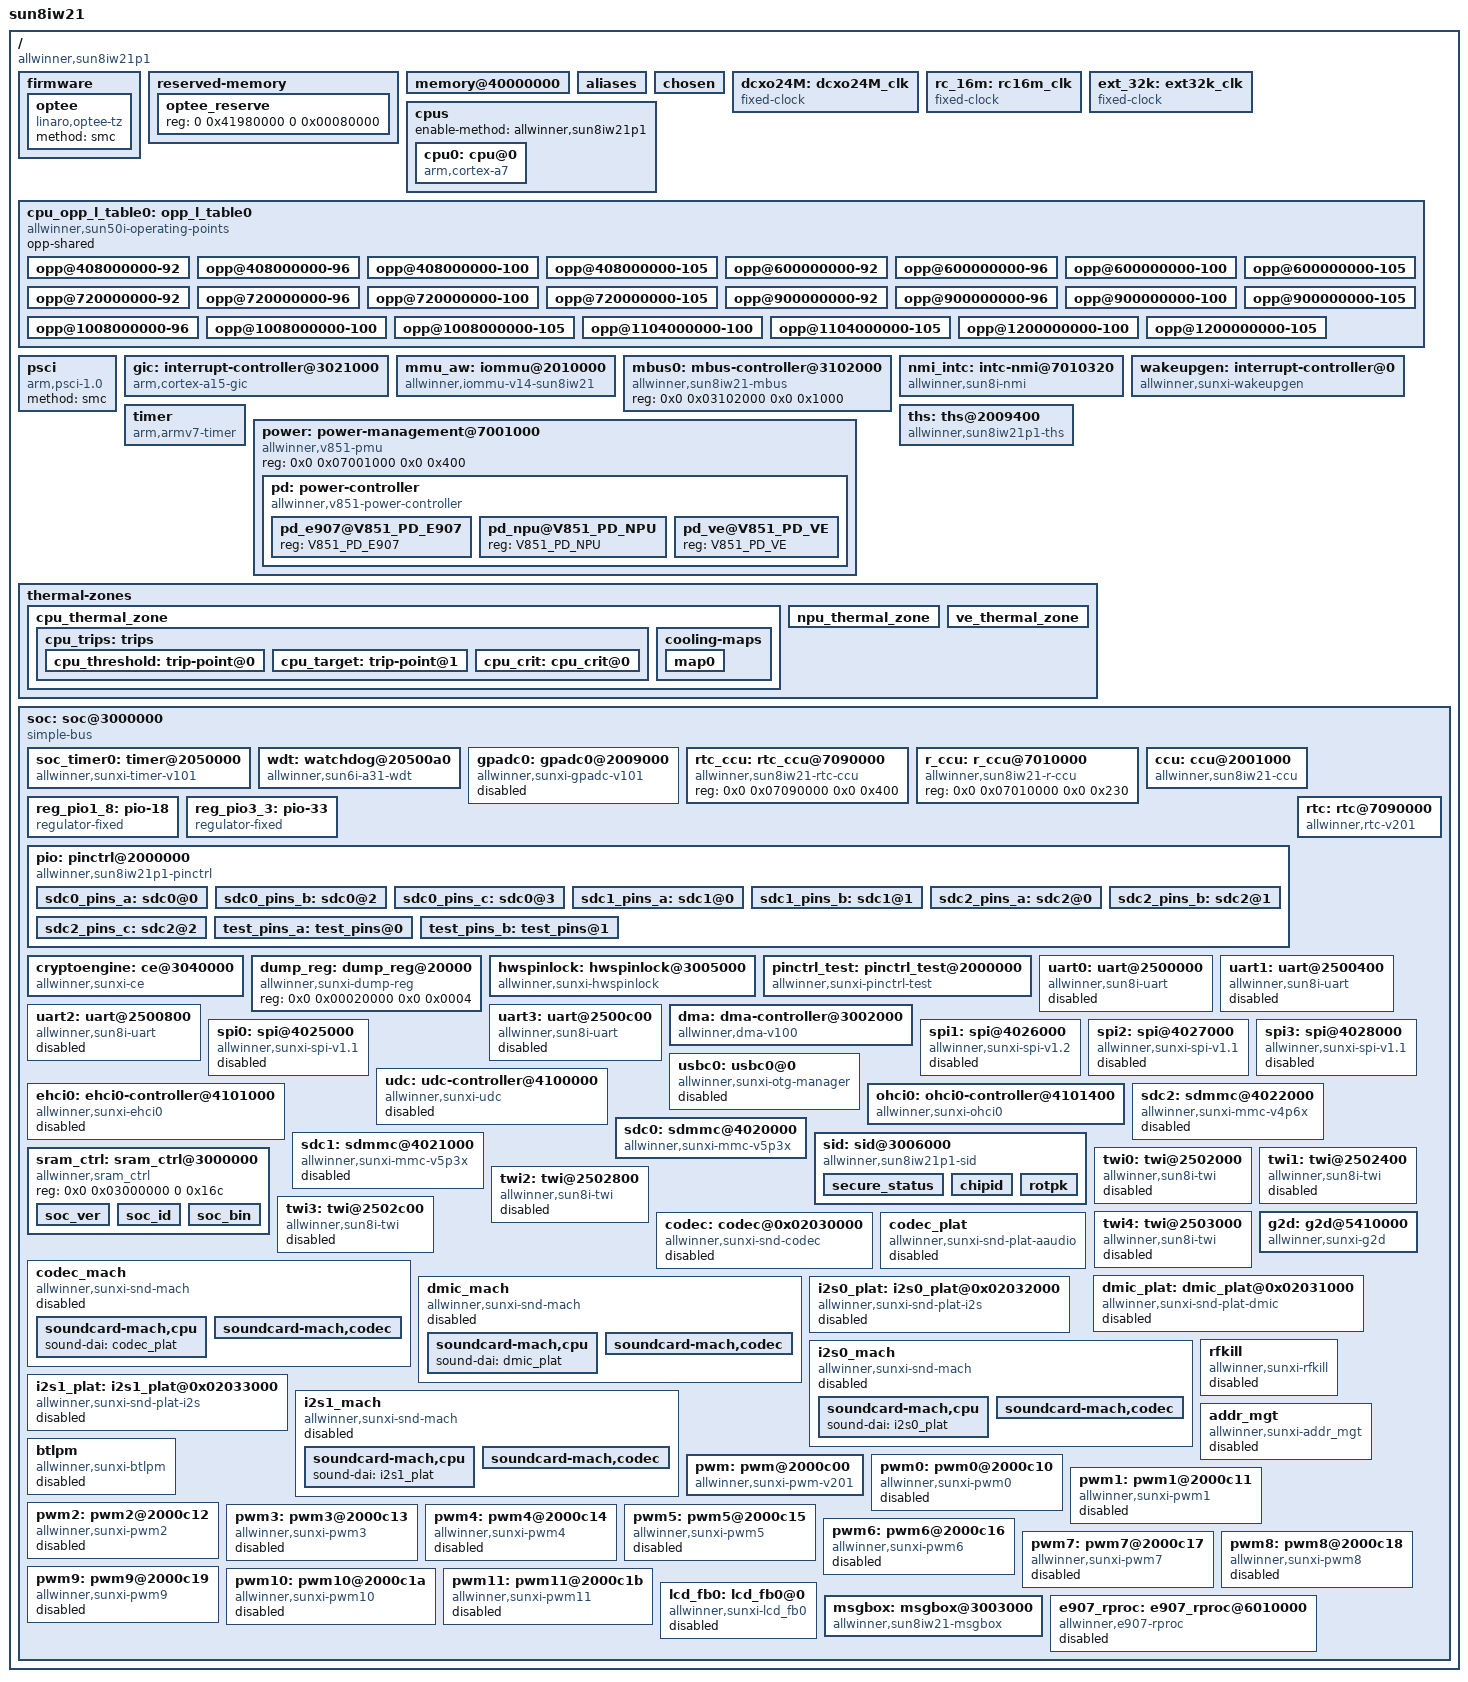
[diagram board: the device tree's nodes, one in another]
/* SPDX-License-Identifier: GPL-2.0-or-later */
/*
 * Allwinner Technology CO., Ltd. sun8iw21p1 platform
 *
 * modify base on juno.dts
 */

/* kernel used */
#include <dt-bindings/interrupt-controller/arm-gic.h>
#include <dt-bindings/gpio/gpio.h>
#include <dt-bindings/thermal/thermal.h>
#include <dt-bindings/power/v851-power.h>
#include <dt-bindings/reset/sun8iw21-ccu.h>
#include <dt-bindings/reset/sun8iw21-r-ccu.h>
#include <dt-bindings/clock/sun8iw21-ccu.h>
#include <dt-bindings/clock/sun8iw21-rtc.h>
#include <dt-bindings/clock/sun8iw21-r-ccu.h>
#include <dt-bindings/gpio/sun4i-gpio.h>
#include <dt-bindings/spi/sunxi-spi.h>

/ {
	model = "sun8iw21";
	compatible = "allwinner,sun8iw21p1";
	interrupt-parent = <&wakeupgen>;
	#address-cells = <2>;
	#size-cells = <2>;

	firmware {
		optee {
			compatible = "linaro,optee-tz";
			method = "smc";
		};
	};

	reserved-memory {
		#address-cells = <2>;
		#size-cells = <2>;
		ranges;

		optee_reserve {
			reg = <0 0x41980000 0 0x00080000>; /* size must be set 0x80000 in secure */
			status = "okay";
		};
	};

	memory@40000000 {
		device_type = "memory";
		reg = <0x00000000 0x40000000 0x00000000 0x20000000>;
	};

	aliases {
		serial0 = &uart0;
		serial1 = &uart1;
		serial2 = &uart2;
		serial3 = &uart3;
		spi0 = &spi0;
		spi1 = &spi1;
		spi2 = &spi2;
		spi3 = &spi3;
		gpadc0 = &gpadc0;
		sunxi-mmc0 = &sdc0;
		sunxi-mmc2 = &sdc2;
		twi0 = &twi0;
		twi1 = &twi1;
		twi2 = &twi2;
		twi3 = &twi3;
		twi4 = &twi4;
	};

	chosen {
		bootargs = "earlyprintk=sunxi-uart,0x02500000 loglevel=8 initcall_debug=0 console=ttyS0 init=/init";
		linux,initrd-start = <0x0 0x0>;
		linux,initrd-end = <0x0 0x0>;
	};

	dcxo24M: dcxo24M_clk {
		#clock-cells = <0>;
		compatible = "fixed-clock";
		clock-frequency = <24000000>;
		clock-output-names = "dcxo24M";
	};

	rc_16m: rc16m_clk {
		#clock-cells = <0>;
		compatible = "fixed-clock";
		clock-frequency = <16000000>;
		clock-accuracy = <300000000>;
		clock-output-names = "rc-16m";
	};

	ext_32k: ext32k_clk {
		#clock-cells = <0>;
		compatible = "fixed-clock";
		clock-frequency = <32768>;
		clock-output-names = "ext-32k";
	};

	cpus {
		enable-method = "allwinner,sun8iw21p1";
		#address-cells = <1>;
		#size-cells = <0>;

		cpu0: cpu@0 {
			device_type = "cpu";
			compatible = "arm,cortex-a7";
			reg = <0x0>;
			enable-method = "psci";
			vf_tbl_sel = <0>;
			clocks = <&ccu CLK_CPU>;
			clock-frequency = <1008000000>;
			clock-latency = <2000000>;
			cooling-min-level = <5>;
			cooling-max-level = <0>;
			#cooling-cells = <2>; /* min followed by max */
			dynamic-power-coefficient = <142>;
			operating-points-v2 = <&cpu_opp_l_table0>;
		};

	};

	cpu_opp_l_table0: opp_l_table0 {
		/* compatible = "operating-points-v2"; */
		compatible = "allwinner,sun50i-operating-points";
		opp-shared;
		/* compatible = "allwinner,opp_l_table0"; */

		opp@408000000-92 {
			opp-hz = /bits/ 64 <408000000>;
			opp-microvolt = <920000>;
			clock-latency-ns = <244144>; /* 8 32k periods */
			opp-supported-hw = <0x42B>;
		};
		opp@408000000-96 {
			opp-hz = /bits/ 64 <408000000>;
			opp-microvolt = <960000>;
			clock-latency-ns = <244144>; /* 8 32k periods */
			opp-supported-hw = <0xA54>;
		};
		opp@408000000-100 {
			opp-hz = /bits/ 64 <408000000>;
			opp-microvolt = <1000000>;
			clock-latency-ns = <244144>; /* 8 32k periods */
			opp-supported-hw = <0x80>;
		};
		opp@408000000-105 {
			opp-hz = /bits/ 64 <408000000>;
			opp-microvolt = <1050000>;
			clock-latency-ns = <244144>; /* 8 32k periods */
			opp-supported-hw = <0x100>;
		};
		opp@600000000-92 {
			opp-hz = /bits/ 64 <600000000>;
			opp-microvolt = <920000>;
			clock-latency-ns = <244144>; /* 8 32k periods */
			opp-supported-hw = <0x42B>;
		};
		opp@600000000-96 {
			opp-hz = /bits/ 64 <600000000>;
			opp-microvolt = <960000>;
			clock-latency-ns = <244144>; /* 8 32k periods */
			opp-supported-hw = <0xA54>;
		};
		opp@600000000-100 {
			opp-hz = /bits/ 64 <600000000>;
			opp-microvolt = <1000000>;
			clock-latency-ns = <244144>; /* 8 32k periods */
			opp-supported-hw = <0x80>;
		};
		opp@600000000-105 {
			opp-hz = /bits/ 64 <600000000>;
			opp-microvolt = <1050000>;
			clock-latency-ns = <244144>; /* 8 32k periods */
			opp-supported-hw = <0x100>;
		};
		opp@720000000-92 {
			opp-hz = /bits/ 64 <720000000>;
			opp-microvolt = <920000>;
			clock-latency-ns = <244144>; /* 8 32k periods */
			opp-supported-hw = <0x42B>;
		};
		opp@720000000-96 {
			opp-hz = /bits/ 64 <720000000>;
			opp-microvolt = <960000>;
			clock-latency-ns = <244144>; /* 8 32k periods */
			opp-supported-hw = <0xA54>;
		};
		opp@720000000-100 {
			opp-hz = /bits/ 64 <720000000>;
			opp-microvolt = <1000000>;
			clock-latency-ns = <244144>; /* 8 32k periods */
			opp-supported-hw = <0x80>;
		};
		opp@720000000-105 {
			opp-hz = /bits/ 64 <720000000>;
			opp-microvolt = <1050000>;
			clock-latency-ns = <244144>; /* 8 32k periods */
			opp-supported-hw = <0x100>;
		};
		opp@900000000-92 {
			opp-hz = /bits/ 64 <900000000>;
			opp-microvolt = <920000>;
			clock-latency-ns = <244144>; /* 8 32k periods */
			opp-supported-hw = <0x42B>;
		};
		opp@900000000-96 {
			opp-hz = /bits/ 64 <900000000>;
			opp-microvolt = <960000>;
			clock-latency-ns = <244144>; /* 8 32k periods */
			opp-supported-hw = <0xA54>;
		};
		opp@900000000-100 {
			opp-hz = /bits/ 64 <900000000>;
			opp-microvolt = <1000000>;
			clock-latency-ns = <244144>; /* 8 32k periods */
			opp-supported-hw = <0x80>;
		};
		opp@900000000-105 {
			opp-hz = /bits/ 64 <900000000>;
			opp-microvolt = <1050000>;
			clock-latency-ns = <244144>; /* 8 32k periods */
			opp-supported-hw = <0x100>;
		};
		opp@1008000000-96 {
			opp-hz = /bits/ 64 <1008000000>;
			opp-microvolt = <960000>;
			clock-latency-ns = <244144>; /* 8 32k periods */
			opp-supported-hw = <0xE54>;
		};
		opp@1008000000-100 {
			opp-hz = /bits/ 64 <1008000000>;
			opp-microvolt = <1000000>;
			clock-latency-ns = <244144>; /* 8 32k periods */
			opp-supported-hw = <0x80>;
		};
		opp@1008000000-105 {
			opp-hz = /bits/ 64 <1008000000>;
			opp-microvolt = <1050000>;
			clock-latency-ns = <244144>; /* 8 32k periods */
			opp-supported-hw = <0x100>;
		};
		opp@1104000000-100 {
			opp-hz = /bits/ 64 <1104000000>;
			opp-microvolt = <1000000>;
			clock-latency-ns = <244144>; /* 8 32k periods */
			opp-supported-hw = <0xC80>;
		};
		opp@1104000000-105 {
			opp-hz = /bits/ 64 <1104000000>;
			opp-microvolt = <1050000>;
			clock-latency-ns = <244144>; /* 8 32k periods */
			opp-supported-hw = <0x100>;
		};
		opp@1200000000-100 {
			opp-hz = /bits/ 64 <1200000000>;
			opp-microvolt = <1000000>;
			clock-latency-ns = <244144>; /* 8 32k periods */
			opp-supported-hw = <0x80>;
		};
		opp@1200000000-105 {
			opp-hz = /bits/ 64 <1200000000>;
			opp-microvolt = <1050000>;
			clock-latency-ns = <244144>; /* 8 32k periods */
			opp-supported-hw = <0x100>;
		};
	};

	psci {
		compatible = "arm,psci-1.0";
		method = "smc";
	};

	gic: interrupt-controller@3021000 {
		compatible = "arm,cortex-a15-gic", "arm,cortex-a9-gic";
		#interrupt-cells = <3>;
		#address-cells = <0>;
		device_type = "gic";
		interrupt-controller;
		reg = <0x0 0x03021000 0 0x1000>, /* GIC Dist */
		      <0x0 0x03022000 0 0x2000>, /* GIC CPU */
		      <0x0 0x03024000 0 0x2000>, /* GIC VCPU Control */
		      <0x0 0x03026000 0 0x2000>; /* GIC VCPU */
		interrupts = <GIC_PPI 9 0xf04>; /* GIC Maintenence IRQ */
		interrupt-parent = <&gic>;
	};

	mmu_aw: iommu@2010000 {
		compatible = "allwinner,iommu-v14-sun8iw21";
		reg = <0x0 0x02010000 0x0 0x400>;
		interrupts = <GIC_SPI 64 IRQ_TYPE_LEVEL_HIGH>;
		interrupt-names = "iommu-irq";
		clocks = <&ccu CLK_IOMMU>;
		clock-names = "iommu";
		/* clock-frequency = <24000000>; */
		#iommu-cells = <2>;
		status = "okay";
	};

	mbus0: mbus-controller@3102000 {
		compatible = "allwinner,sun8iw21-mbus";
		reg = <0x0 0x03102000 0x0 0x1000>;
		#mbus-cells = <1>;
		status = "okay";
	};

	nmi_intc: intc-nmi@7010320 {
		compatible = "allwinner,sun8i-nmi";
		interrupt-parent = <&gic>;
		#interrupt-cells = <2>;
		#address-cells = <0>;
		interrupt-controller;
		reg = <0x0 0x07010320 0 0xc>;
		pad-control-v2 = <0x07090230>;
		pad-control-offset = <30>;
		pad-control-en = <0>;
		interrupts = <GIC_SPI 136 IRQ_TYPE_LEVEL_HIGH>;
	};

	wakeupgen: interrupt-controller@0 {
		compatible = "allwinner,sunxi-wakeupgen";
		interrupt-controller;
		#interrupt-cells = <3>;
		interrupt-parent = <&gic>;
	};

	timer {
		compatible = "arm,armv7-timer";
		interrupts = <GIC_PPI 13 (GIC_CPU_MASK_SIMPLE(2) | IRQ_TYPE_LEVEL_LOW)>, /* Secure Phys IRQ */
			     <GIC_PPI 14 (GIC_CPU_MASK_SIMPLE(2) | IRQ_TYPE_LEVEL_LOW)>, /* Non-secure Phys IRQ */
			     <GIC_PPI 11 (GIC_CPU_MASK_SIMPLE(2) | IRQ_TYPE_LEVEL_LOW)>, /* Virt IRQ */
			     <GIC_PPI 10 (GIC_CPU_MASK_SIMPLE(2) | IRQ_TYPE_LEVEL_LOW)>; /* Hyp IRQ */
		clock-frequency = <24000000>;
		arm,cpu-registers-not-fw-configured;
		interrupt-parent = <&gic>;
		arm,no-tick-in-suspend;
	};

	power: power-management@7001000 {
		compatible = "allwinner,v851-pmu", "syscon", "simple-mfd";
		reg = <0x0 0x07001000 0x0 0x400>;

		pd: power-controller {
			compatible = "allwinner,v851-power-controller";
			clocks = <&r_ccu CLK_R_PPU>;
			clock-names = "ppu";
			resets = <&r_ccu RST_BUS_R_PPU>;
			reset-names = "ppu_rst";
			#power-domain-cells = <1>;
			#address-cells = <1>;
			#size-cells = <0>;

			pd_e907@V851_PD_E907 {
				reg = <V851_PD_E907>;
			};
			pd_npu@V851_PD_NPU {
				reg = <V851_PD_NPU>;
			};
			pd_ve@V851_PD_VE {
				reg = <V851_PD_VE>;
			};
		};
	};

	ths: ths@2009400 {
		compatible = "allwinner,sun8iw21p1-ths";
		reg = <0x0 0x02009400 0x0 0x400>;
		clocks = <&ccu CLK_THS>,<&ccu CLK_GPADC_24M>;
		clock-names = "bus","gpadc";
		resets = <&ccu RST_BUS_TH>;
		#thermal-sensor-cells = <1>;
	};

	thermal-zones {
		cpu_thermal_zone {
			polling-delay-passive = <500>;
			polling-delay = <1000>;
			thermal-sensors = <&ths 2>;
			sustainable-power = <68>;

			cpu_trips: trips {
				cpu_threshold: trip-point@0 {
					temperature = <70000>;
					type = "passive";
					hysteresis = <0>;
				};
				cpu_target: trip-point@1 {
					temperature = <90000>;
					type = "passive";
					hysteresis = <0>;
				};
				cpu_crit: cpu_crit@0 {
					temperature = <110000>;
					type = "critical";
					hysteresis = <0>;
				};
			};

			cooling-maps {
				map0 {
					trip = <&cpu_target>;
					cooling-device = <&cpu0
					THERMAL_NO_LIMIT
					THERMAL_NO_LIMIT>;
					contribution = <1024>;
				};
			};
		};
		npu_thermal_zone {
			polling-delay-passive = <0>;
			polling-delay = <0>;
			thermal-sensors = <&ths 0>;
		};
		ve_thermal_zone {
			polling-delay-passive = <0>;
			polling-delay = <0>;
			thermal-sensors = <&ths 1>;
		};
	};

	soc: soc@3000000 {
		compatible = "simple-bus";
		#address-cells = <2>;
		#size-cells = <2>;
		ranges;
		device_type = "soc";

		soc_timer0: timer@2050000 {
			compatible = "allwinner,sunxi-timer-v101";
			device_type = "soc_timer";
			reg = <0x0 0x02050000 0x0 0x90>;
			interrupts = <GIC_SPI 59 IRQ_TYPE_LEVEL_HIGH>;
			clocks = <&dcxo24M>, <&rtc_ccu CLK_OSC32K>;
		};

		wdt: watchdog@20500a0 {
			compatible = "allwinner,sun6i-a31-wdt";
			reg = <0x0 0x020500a0 0x0 0x20>;
			interrupts = <GIC_SPI 63 IRQ_TYPE_LEVEL_HIGH>;
		};

		gpadc0: gpadc0@2009000 {
			compatible = "allwinner,sunxi-gpadc-v101";
			reg = <0x0 0x02009000 0x0 0x400>;
			interrupts = <GIC_SPI 57 IRQ_TYPE_LEVEL_HIGH>;
			clocks = <&ccu CLK_GPADC>, <&ccu CLK_GPADC_24M>;
			clock-names = "bus", "hosc";
			resets = <&ccu RST_BUS_GPADC>;
			status = "disabled";
		};

		rtc_ccu: rtc_ccu@7090000 {
			compatible = "allwinner,sun8iw21-rtc-ccu";
			reg = <0x0 0x07090000 0x0 0x400>;
			#clock-cells = <1>;
			#reset-cells = <1>;
		};

		r_ccu: r_ccu@7010000 {
			compatible = "allwinner,sun8iw21-r-ccu";
			reg = <0x0 0x07010000 0x0 0x230>;
			#clock-cells = <1>;
			#reset-cells = <1>;
		};

		ccu: ccu@2001000 {
			compatible = "allwinner,sun8iw21-ccu";
			reg = <0x0 0x02001000 0x0 0x1000>;
			clocks = <&dcxo24M>, <&rtc_ccu CLK_OSC32K>, <&rc_16m>;
			clock-names = "hosc", "losc", "iosc";
			#clock-cells = <1>;
			#reset-cells = <1>;
		};

		reg_pio1_8: pio-18 {
			compatible = "regulator-fixed";
			regulator-name = "pio-18";
			regulator-min-microvolt = <1800000>;
			regulator-max-microvolt = <1800000>;
		};

		reg_pio3_3: pio-33 {
			compatible = "regulator-fixed";
			regulator-name = "pio-33";
			regulator-min-microvolt = <3300000>;
			regulator-max-microvolt = <3300000>;
		};

		pio: pinctrl@2000000 {
			compatible = "allwinner,sun8iw21p1-pinctrl";
			reg = <0x0 0x02000000 0x0 0x400>;
			interrupts = <GIC_SPI 67 IRQ_TYPE_LEVEL_HIGH>,
				     <GIC_SPI 71 IRQ_TYPE_LEVEL_HIGH>,
				     <GIC_SPI 73 IRQ_TYPE_LEVEL_HIGH>,
				     <GIC_SPI 75 IRQ_TYPE_LEVEL_HIGH>,
				     <GIC_SPI 77 IRQ_TYPE_LEVEL_HIGH>,
				     <GIC_SPI 79 IRQ_TYPE_LEVEL_HIGH>,
				     <GIC_SPI 81 IRQ_TYPE_LEVEL_HIGH>,
				     <GIC_SPI 83 IRQ_TYPE_LEVEL_HIGH>;
			device_type = "pio";
			clocks = <&ccu CLK_APB0>, <&dcxo24M>, <&rtc_ccu CLK_OSC32K>;
			clock-names = "apb", "hosc", "losc";
			gpio-controller;
			interrupt-controller;
			#interrupt-cells = <3>;
			#size-cells = <0>;
			#gpio-cells = <3>;

			sdc0_pins_a: sdc0@0 {
				pins = "PF0", "PF1", "PF2",
						 "PF3", "PF4", "PF5";
				function = "sdc0";
				drive-strength = <40>;
				bias-pull-up;
				power-source = <3300>;
			};

			sdc0_pins_b: sdc0@2 {
				pins = "PF0", "PF1", "PF2",
						 "PF3", "PF4", "PF5";
				function = "io_disabled";
				power-source = <3300>;
			};

			sdc0_pins_c: sdc0@3 {
				pins = "PF0", "PF1", "PF2",
						 "PF3", "PF4", "PF5";
				function = "uart0_jtag";
				drive-strength = <10>;
				bias-pull-up;
			};

			sdc1_pins_a: sdc1@0 {
				pins = "PE0", "PE1", "PE2",
						 "PE3", "PE4", "PE5";
				function = "sdc1";
				drive-strength = <40>;
				bias-pull-up;
			};

			sdc1_pins_b: sdc1@1 {
				pins = "PE0", "PE1", "PE2",
						 "PE3", "PE4", "PE5";
				function = "io_disabled";
			};

			sdc2_pins_a: sdc2@0 {
				pins = "PC1", "PC4", "PC5", "PC6",
						 "PC7", "PC8", "PC9",
						 "PC11", "PC2", "PC3", "PC0";
				function = "sdc2";
				drive-strength = <40>;
				bias-pull-up;
			};

			sdc2_pins_b: sdc2@1 {
				pins = "PC1", "PC4", "PC5", "PC6",
						 "PC7", "PC8", "PC9",
						 "PC11", "PC2", "PC3", "PC10",
						 "PC0";
				function = "io_disabled";
			};

			sdc2_pins_c: sdc2@2 {
				pins = "PC10";
				function = "sdc2";
				drive-strength = <40>;
				bias-pull-down;
			};

			test_pins_a: test_pins@0 {
				pins = "PA0", "PA1";
				function = "test";
				drive-strength = <10>;
				bias-pull-up;
			};

			test_pins_b: test_pins@1 {
				pins = "PA0", "PA1";
				function = "gpio_in";
			};
		};

		rtc: rtc@7090000 {
			compatible = "allwinner,rtc-v201";
			device_type = "rtc";
			wakeup-source;
			reg = <0x0 0x07090000 0x0 0x320>;
			interrupts = <GIC_SPI 138 IRQ_TYPE_LEVEL_HIGH>;
			clocks = <&r_ccu CLK_R_RTC>;
			clock-names = "r-ahb-rtc";
			resets = <&r_ccu RST_BUS_R_RTC>;
			gpr_cur_pos = <6>;
			gpr_bootcount_pos = <7>;
			status = "okay";
		};

		cryptoengine: ce@3040000 {
			compatible = "allwinner,sunxi-ce";
			device_name = "ce";
			reg = <0x0 0x3040000 0x0 0x200>, /* non-secure space */
				<0x0 0x3040800 0x0 0x200>; /* secure space */
			interrupts = <GIC_SPI 52 IRQ_TYPE_EDGE_RISING>, /*non-secure*/
				<GIC_SPI 53 IRQ_TYPE_EDGE_RISING>; /* secure */
			clock-frequency = <400000000>; /* 400MHz */
			clocks = <&ccu CLK_BUS_CE>, <&ccu CLK_CE>, <&ccu CLK_MBUS_CE_GATE>,
					<&ccu CLK_PLL_PERI_400M>, <&ccu CLK_CE_SYS>;
			clock-names = "bus_ce", "ce_clk", "mbus_ce", "clk_src", "ce_sys_clk";
			resets = <&ccu RST_BUS_CE>;
			status = "okay";
		};

		dump_reg:dump_reg@20000 {
			compatible = "allwinner,sunxi-dump-reg";
			reg = <0x0 0x00020000 0x0 0x0004>;
			status = "okay";
		};

		hwspinlock: hwspinlock@3005000 {
			compatible = "allwinner,sunxi-hwspinlock";
			reg = <0x0 0x3005000 0x0 0x1000>;
			#hwlock-cells = <1>;
			clocks = <&ccu CLK_SPINLOCK>;
			clock-names = "clk_hwspinlock_bus";
			resets = <&ccu RST_BUS_SPINLOCK>;
			reset-names = "rst";
			num-locks = <32>;
			status = "okay";
		};

		pinctrl_test: pinctrl_test@2000000 {
			reg = <0x0 0x0 0x0 0x0>;
			compatible = "allwinner,sunxi-pinctrl-test";
			device_type = "pinctrl-test";
			pinctrl-0 = <&test_pins_a>;
			pinctrl-1 = <&test_pins_b>;
			pinctrl-names = "default", "sleep";
			test-gpios = <&pio PC 4 GPIO_ACTIVE_LOW>;
			suspend-gpios = <&pio PC 5 GPIO_ACTIVE_LOW>;
			wakeup-source;
			interrupt-parent = <&pio>;
			interrupts = <PC 6 IRQ_TYPE_LEVEL_HIGH>;
		};

		uart0: uart@2500000 {
			compatible = "allwinner,sun8i-uart";
			device_type = "uart0";
			reg = <0x0 0x02500000 0x0 0x400>;
			interrupts = <GIC_SPI 2 IRQ_TYPE_LEVEL_HIGH>;
			clocks = <&ccu CLK_UART0>;
			resets = <&ccu RST_BUS_UART0>;
			sunxi,uart-fifosize = <64>;
			uart0_port = <0>;
			uart0_type = <2>;
			status = "disabled";
		};

		uart1: uart@2500400 {
			compatible = "allwinner,sun8i-uart";
			device_type = "uart1";
			reg = <0x0 0x02500400 0x0 0x400>;
			interrupts = <GIC_SPI 3 IRQ_TYPE_LEVEL_HIGH>;
			clocks = <&ccu CLK_UART1>;
			resets = <&ccu RST_BUS_UART1>;
			sunxi,uart-fifosize = <128>;
			uart1_port = <1>;
			uart1_type = <4>;
			status = "disabled";
		};

		uart2: uart@2500800 {
			compatible = "allwinner,sun8i-uart";
			device_type = "uart2";
			reg = <0x0 0x02500800 0x0 0x400>;
			interrupts = <GIC_SPI 4 IRQ_TYPE_LEVEL_HIGH>;
			clocks = <&ccu CLK_UART2>;
			resets = <&ccu RST_BUS_UART2>;
			sunxi,uart-fifosize = <128>;
			uart2_port = <2>;
			uart2_type = <4>;
			status = "disabled";
		};

		uart3: uart@2500c00 {
			compatible = "allwinner,sun8i-uart";
			device_type = "uart3";
			reg = <0x0 0x02500c00 0x0 0x400>;
			interrupts = <GIC_SPI 5 IRQ_TYPE_LEVEL_HIGH>;
			clocks = <&ccu CLK_UART3>;
			resets = <&ccu RST_BUS_UART3>;
			sunxi,uart-fifosize = <128>;
			uart3_port = <3>;
			uart3_type = <4>;
			status = "disabled";
		};

		dma: dma-controller@3002000 {
			compatible = "allwinner,dma-v100";
			reg = <0x0 0x03002000 0x0 0x1000>;
			interrupts = <GIC_SPI 50 IRQ_TYPE_LEVEL_HIGH>;
			clocks = <&ccu CLK_DMA>, <&ccu CLK_MBUS_DMA>;
			clock-names = "bus", "mbus";
			dma-channels = <16>;
			dma-requests = <48>;
			resets = <&ccu RST_BUS_DMA>;
			#dma-cells = <1>;
			status = "okay";
		};

		spi0: spi@4025000 {
			#address-cells = <1>;
			#size-cells = <0>;
			compatible = "allwinner,sunxi-spi-v1.1";
			device_type = "spi0";
			reg = <0x0 0x04025000 0x0 0x1000>;
			interrupts = <GIC_SPI 15 IRQ_TYPE_LEVEL_HIGH>;
			clocks = <&ccu CLK_PLL_PERI_300M>, <&ccu CLK_SPI0>, <&ccu CLK_BUS_SPI0>;
			clock-names = "pll", "mod", "bus";
			resets = <&ccu RST_BUS_SPI0>;
			dmas = <&dma 22>, <&dma 22>;
			dma-names = "tx", "rx";
			clock-frequency = <100000000>;
			sunxi,spi-num-cs = <2>;
			status = "disabled";
		};

		spi1: spi@4026000 {
			#address-cells = <1>;
			#size-cells = <0>;
			compatible = "allwinner,sunxi-spi-v1.2";
			device_type = "spi1";
			reg = <0x0 0x04026000 0x0 0x1000>;
			interrupts = <GIC_SPI 16 IRQ_TYPE_LEVEL_HIGH>;
			clocks = <&ccu CLK_PLL_PERI_300M>, <&ccu CLK_SPI1>, <&ccu CLK_BUS_SPI1>;
			clock-names = "pll", "mod", "bus";
			resets = <&ccu RST_BUS_SPI1>;
			dmas = <&dma 23>, <&dma 23>;
			dma-names = "tx", "rx";
			clock-frequency = <100000000>;
			sunxi,spi-num-cs = <2>;
			status = "disabled";
		};

		spi2: spi@4027000 {
			#address-cells = <1>;
			#size-cells = <0>;
			compatible = "allwinner,sunxi-spi-v1.1";
			device_type = "spi2";
			reg = <0x0 0x04027000 0x0 0x1000>;
			interrupts = <GIC_SPI 17 IRQ_TYPE_LEVEL_HIGH>;
			clocks = <&ccu CLK_PLL_PERI_300M>, <&ccu CLK_SPI2>, <&ccu CLK_BUS_SPI2>;
			clock-names = "pll", "mod", "bus";
			resets = <&ccu RST_BUS_SPI2>;
			dmas = <&dma 24>, <&dma 24>;
			dma-names = "tx", "rx";
			clock-frequency = <100000000>;
			sunxi,spi-num-cs = <2>;
			status = "disabled";
		};

		spi3: spi@4028000 {
			#address-cells = <1>;
			#size-cells = <0>;
			compatible = "allwinner,sunxi-spi-v1.1";
			device_type = "spi3";
			reg = <0x0 0x04028000 0x0 0x1000>;
			interrupts = <GIC_SPI 21 IRQ_TYPE_LEVEL_HIGH>;
			clocks = <&ccu CLK_PLL_PERI_300M>, <&ccu CLK_SPI3>, <&ccu CLK_BUS_SPI3>;
			clock-names = "pll", "mod", "bus";
			resets = <&ccu RST_BUS_SPI3>;
			dmas = <&dma 25>, <&dma 25>;
			dma-names = "tx", "rx";
			clock-frequency = <100000000>;
			sunxi,spi-num-cs = <2>;
			status = "disabled";
		};

		usbc0:usbc0@0 {
			device_type = "usbc0";
			compatible = "allwinner,sunxi-otg-manager";
			usb_port_type = <2>;
			usb_detect_type = <1>;
			usb_id_gpio;
			usb_det_vbus_gpio;
			usb_drv_vbus_gpio;
			usb_host_init_state = <0>;
			usb_regulator_io = "nocare";
			usb_wakeup_suspend = <0>;
			usb_luns = <3>;
			usb_serial_unique = <0>;
			usb_serial_number = "20080411";
			rndis_wceis = <1>;
			/* wakeup-source; */
			status = "disabled";
		};

		udc:udc-controller@4100000 {
			compatible = "allwinner,sunxi-udc";
			reg = <0x0 0x04100000 0x0 0x1000>,
			      <0x0 0x00000000 0x0 0x100>;
			interrupts = <GIC_SPI 29 IRQ_TYPE_LEVEL_HIGH>;
			clocks = <&ccu CLK_USBOTG0>;
			clock-names = "bus_otg";
			resets = <&ccu RST_USB_OTG0>, <&ccu RST_USB_PHY0_RSTN>;
			reset-names = "otg", "phy";
			status = "disabled";
		};

		ehci0:ehci0-controller@4101000 {
			compatible = "allwinner,sunxi-ehci0";
			reg = <0x0 0x04101000 0x0 0xFFF>,
			      <0x0 0x00000000 0x0 0x100>,
			      <0x0 0x04100000 0x0 0x1000>;
			interrupts = <GIC_SPI 30 IRQ_TYPE_LEVEL_HIGH>;
			clocks = <&ccu CLK_USBEHCI0>;
			clock-names = "bus_hci";
			resets = <&ccu RST_USB_EHCI0>, <&ccu RST_USB_PHY0_RSTN>;
			reset-names = "hci", "phy";
			hci_ctrl_no = <0>;
			status = "disabled";
		};

		ohci0:ohci0-controller@4101400 {
			compatible = "allwinner,sunxi-ohci0";
			reg = <0x0 0x04101400 0x0 0xFFF>,
			      <0x0 0x00000000 0x0 0x100>,
			      <0x0 0x04100000 0x0 0x1000>;
			interrupts = <GIC_SPI 31 IRQ_TYPE_LEVEL_HIGH>;
			clocks = <&ccu CLK_USBOHCI0>, <&ccu CLK_USB>;
			clock-names = "bus_hci", "ohci";
			resets = <&ccu RST_USB_OHCI0>, <&ccu RST_USB_PHY0_RSTN>;
			reset-names = "hci", "phy";
			hci_ctrl_no = <0>;
		};

		sdc2: sdmmc@4022000 {
			compatible = "allwinner,sunxi-mmc-v4p6x";
			device_type = "sdc2";
			reg = <0x0 0x04022000 0x0 0x1000>;
			interrupts = <GIC_SPI 42 IRQ_TYPE_LEVEL_HIGH>;
			clocks = <&dcxo24M>,
				<&ccu CLK_PLL_PERI_600M>,
				<&ccu CLK_PLL_PERI_400M>,
				<&ccu CLK_SMHC2>,
				<&ccu CLK_BUS_SMHC2>;
			clock-names = "osc24m","pll_periph","pll_periph_2","mmc","ahb";
			resets = <&ccu RST_BUS_SMHC2>;
			reset-names = "rst";
			pinctrl-names = "default","sleep";
			pinctrl-0 = <&sdc2_pins_a &sdc2_pins_c>;
			pinctrl-1 = <&sdc2_pins_b>;
			bus-width = <8>;
			req-page-count = <2>;
			cap-mmc-highspeed;
			cap-cmd23;
			mmc-cache-ctrl;
			non-removable;
			/*max-frequency = <200000000>;*/
			max-frequency = <50000000>;
			cap-erase;
			mmc-high-capacity-erase-size;
			no-sdio;
			no-sd;
			/*-- speed mode --*/
			/*sm0: DS26_SDR12*/
			/*sm1: HSSDR52_SDR25*/
			/*sm2: HSDDR52_DDR50*/
			/*sm3: HS200_SDR104*/
			/*sm4: HS400*/
			/*-- frequency point --*/
			/*f0: CLK_400K*/
			/*f1: CLK_25M*/
			/*f2: CLK_50M*/
			/*f3: CLK_100M*/
			/*f4: CLK_150M*/
			/*f5: CLK_200M*/

			sdc_tm4_sm0_freq0 = <0>;
			sdc_tm4_sm0_freq1 = <0>;
			sdc_tm4_sm1_freq0 = <0x00000000>;
			sdc_tm4_sm1_freq1 = <0>;
			sdc_tm4_sm2_freq0 = <0x00000000>;
			sdc_tm4_sm2_freq1 = <0>;
			sdc_tm4_sm3_freq0 = <0x05000000>;
			sdc_tm4_sm3_freq1 = <0x00000005>;
			sdc_tm4_sm4_freq0 = <0x00050000>;
			sdc_tm4_sm4_freq1 = <0x00000004>;
			sdc_tm4_sm4_freq0_cmd = <0>;
			sdc_tm4_sm4_freq1_cmd = <0>;
			ctl-spec-caps = <0x308>;
			/*vmmc-supply = <&reg_3p3v>;*/
			/*vqmc-supply = <&reg_3p3v>;*/
			/*vdmc-supply = <&reg_3p3v>;*/
			/*vmmc = "vcc-card";*/
			/*vqmc = "";*/
			/*vdmc = "";*/
			/*sunxi-power-save-mode;*/
			status = "disabled";
		};

		sdc0: sdmmc@4020000 {
			compatible = "allwinner,sunxi-mmc-v5p3x";
			device_type = "sdc0";
			reg = <0x0 0x04020000 0x0 0x1000>;
			interrupts = <GIC_SPI 40 IRQ_TYPE_LEVEL_HIGH>;
			clocks = <&dcxo24M>,
				 <&ccu CLK_PLL_PERI_400M>,
				 <&ccu CLK_PLL_PERI_300M>,
				 <&ccu CLK_SMHC0>,
				 <&ccu CLK_BUS_SMHC0>;
			clock-names = "osc24m","pll_periph","pll_periph_2","mmc","ahb";
			resets = <&ccu RST_BUS_SMHC0>;
			reset-names = "rst";
			pinctrl-names = "default","sleep","uart_jtag";
			pinctrl-0 = <&sdc0_pins_a>;
			pinctrl-1 = <&sdc0_pins_b>;
			pinctrl-2 = <&sdc0_pins_c>;
			max-frequency = <50000000>;
			bus-width = <4>;
			ctl-spec-caps = <0x8>;
			/*non-removable;*/
			/*broken-cd;*/
			/*cd-inverted*/
			/*cd-gpios = <&pio PF 6 GPIO_ACTIVE_LOW>;*/
			/* vmmc-supply = <&reg_3p3v>;*/
			/* vqmc-supply = <&reg_3p3v>;*/
			/* vdmc-supply = <&reg_3p3v>;*/
			/*vmmc = "vcc-card";*/
			/*vqmc = "";*/
			/*vdmc = "";*/
			cap-sd-highspeed;
			cap-wait-while-busy;
			no-sdio;
			no-mmc;
			/*sd-uhs-sdr50;*/
			/*sd-uhs-ddr50;*/
			/*cap-sdio-irq;*/
			/*keep-power-in-suspend;*/
			/*ignore-pm-notify;*/
			/*sunxi-power-save-mode;*/
			/*sunxi-dly-400k = <1 0 0 0 0 0>; */
			/*sunxi-dly-26M  = <1 0 0 0 0 0>;*/
			/*sunxi-dly-52M  = <1 0 0 0 0 0>;*/
			/*sunxi-dly-52M-ddr4  = <1 0 0 0 0 0>;*/
			/*sunxi-dly-52M-ddr8  = <1 0 0 0 0 0>;*/
			/*sunxi-dly-104M  = <1 0 0 0 0 0>;*/
			sunxi-dly-208M  = <1 1 0 0 0 0>;
			/*sunxi-dly-104M-ddr  = <1 0 0 0 0 0>;*/
			/*sunxi-dly-208M-ddr  = <1 0 0 0 0 0>;*/
		};

		sdc1: sdmmc@4021000 {
			compatible = "allwinner,sunxi-mmc-v5p3x";
			device_type = "sdc1";
			reg = <0x0 0x04021000 0x0 0x1000>;
			interrupts = <GIC_SPI 41 IRQ_TYPE_LEVEL_HIGH>;
			clocks = <&dcxo24M>,
				 <&ccu CLK_PLL_PERI_400M>,
				 <&ccu CLK_PLL_PERI_300M>,
				 <&ccu CLK_SMHC1>,
				 <&ccu CLK_BUS_SMHC1>;
			clock-names = "osc24m","pll_periph","pll_periph_2","mmc","ahb";
			resets = <&ccu RST_BUS_SMHC1>;
			reset-names = "rst";
			pinctrl-names = "default","sleep";
			pinctrl-0 = <&sdc1_pins_a>;
			pinctrl-1 = <&sdc1_pins_b>;
			max-frequency = <50000000>;
			bus-width = <4>;
			ctl-spec-caps = <0x8>;
			/*broken-cd;*/
			/*cd-inverted*/
			/*cd-gpios = <&pio PG 6 6 1 2 0>;*/
			/* vmmc-supply = <&reg_3p3v>;*/
			/* vqmc-supply = <&reg_3p3v>;*/
			/* vdmc-supply = <&reg_3p3v>;*/
			/*vmmc = "vcc-card";*/
			/*vqmc = "";*/
			/*vdmc = "";*/
			/*sd-uhs-sdr50;*/
			/*sd-uhs-ddr50;*/
			/*sd-uhs-sdr104;*/
			cap-sd-highspeed;
			cap-mmc-highspeed;
			cap-wait-while-busy;
			/*cap-sdio-irq;*/
			/*keep-power-in-suspend;*/
			/*ignore-pm-notify;*/
			/*sunxi-power-save-mode;*/
			/*sunxi-dly-400k = <1 0 0 0 0 0>; */
			/*sunxi-dly-26M  = <1 0 0 0 0 0>;*/
			/*sunxi-dly-52M  = <1 0 0 0 0 0>;*/
			/*sunxi-dly-52M-ddr4  = <1 0 0 0 0 2>;*/
			/*sunxi-dly-52M-ddr8  = <1 0 0 0 0 0>;*/
			/*sunxi-dly-104M  = <1 0 0 0 0 1>;*/
			/*sunxi-dly-208M  = <1 1 0 0 0 0>;*/
			sunxi-dly-208M  = <1 1 0 0 0 0>;
			/*sunxi-dly-104M-ddr  = <1 0 0 0 0 0>;*/
			/*sunxi-dly-208M-ddr  = <1 0 0 0 0 0>;*/

			status = "disabled";
		};

		sid: sid@3006000 {
			compatible = "allwinner,sun8iw21p1-sid", "allwinner,sunxi-sid";
			reg = <0x0 0x03006000 0 0x1000>;
			#address-cells = <1>;
			#size-cells = <1>;
			non-secure-maxoffset = <0x38>;
			non-secure-maxlen = <0x20>;

			secure_status {
				reg = <0x0 0>;
				offset = <0xa0>;
				size = <0x4>;
			};
			chipid {
				reg = <0x0 0>;
				offset = <0x200>;
				size = <0x10>;
			};
			rotpk {
				reg = <0x0 0>;
				offset = <0x140>;
				size = <0x20>;
			};

		};

		sram_ctrl: sram_ctrl@3000000 {
			compatible = "allwinner,sram_ctrl";
			reg = <0x0 0x03000000 0 0x16c>;
			soc_ver {
				offset = <0x24>;
				mask = <0x7>;
				shift = <0>;
				ver_a = <0x00000000>;
				ver_b = <0x00000001>;
				ver_c = <0x00000002>;
			};

			soc_id {
				offset = <0x200>;
				mask = <0x1>;
				shift = <22>;
			};

			soc_bin {
				offset = <0x0>;
				mask = <0x3ff>;
				shift = <0x0>;
			};
		};

		twi0: twi@2502000 {
			#address-cells = <1>;
			#size-cells = <0>;
			compatible = "allwinner,sun8i-twi";
			device_type = "twi0";
			reg = <0x0 0x02502000 0x0 0x400>;
			interrupts = <GIC_SPI 9 IRQ_TYPE_LEVEL_HIGH>;
			clocks = <&ccu CLK_TWI0>;
			clock-names = "bus";
			resets = <&ccu RST_BUS_TWI0>;
			status = "disabled";
		};

		twi1: twi@2502400 {
			#address-cells = <1>;
			#size-cells = <0>;
			compatible = "allwinner,sun8i-twi";
			device_type = "twi1";
			reg = <0x0 0x02502400 0x0 0x400>;
			interrupts = <GIC_SPI 10 IRQ_TYPE_LEVEL_HIGH>;
			clocks = <&ccu CLK_TWI1>;
			clock-names = "bus";
			resets = <&ccu RST_BUS_TWI1>;
			status = "disabled";
		};

		twi2: twi@2502800 {
			#address-cells = <1>;
			#size-cells = <0>;
			compatible = "allwinner,sun8i-twi";
			device_type = "twi2";
			reg = <0x0 0x02502800 0x0 0x400>;
			interrupts = <GIC_SPI 11 IRQ_TYPE_LEVEL_HIGH>;
			clocks = <&ccu CLK_TWI2>;
			clock-names = "bus";
			resets = <&ccu RST_BUS_TWI2>;
			status = "disabled";
		};

		twi3: twi@2502c00 {
			#address-cells = <1>;
			#size-cells = <0>;
			compatible = "allwinner,sun8i-twi";
			device_type = "twi3";
			reg = <0x0 0x02502c00 0x0 0x400>;
			interrupts = <GIC_SPI 12 IRQ_TYPE_LEVEL_HIGH>;
			clocks = <&ccu CLK_TWI3>;
			clock-names = "bus";
			resets = <&ccu RST_BUS_TWI3>;
			status = "disabled";
		};

		twi4: twi@2503000 {
			#address-cells = <1>;
			#size-cells = <0>;
			compatible = "allwinner,sun8i-twi";
			device_type = "twi4";
			reg = <0x0 0x02503000 0x0 0x400>;
			interrupts = <GIC_SPI 13 IRQ_TYPE_LEVEL_HIGH>;
			clocks = <&ccu CLK_TWI4>;
			clock-names = "bus";
			resets = <&ccu RST_BUS_TWI4>;
			status = "disabled";
		};

		g2d: g2d@5410000 {
			compatible = "allwinner,sunxi-g2d";
			reg = <0x0 0x05410000 0x0 0x3ffff>;
			interrupts = <GIC_SPI 89 IRQ_TYPE_LEVEL_HIGH>;
			clocks = <&ccu CLK_BUS_G2D>, <&ccu CLK_G2D>, <&ccu CLK_MBUS_G2D>;
			clock-names = "bus", "g2d", "mbus_g2d";
			resets = <&ccu RST_BUS_G2D>;
			iommus = <&mmu_aw 3 1>;
			status = "okay";
		};

		/* audio dirver module -> audio codec */
		codec:codec@0x02030000 {
			#sound-dai-cells = <0>;
			compatible	= "allwinner,sunxi-snd-codec";
			reg		= <0x0 0x02030000 0x0 0x34C>;
			resets		= <&ccu RST_BUS_AUDIO_CODEC>;
			clocks		= <&ccu CLK_AUDIO_CODEC>,
					  <&ccu CLK_PLL_AUDIO_1X>,
					  <&ccu CLK_AUDIO_CODEC_DAC>,
					  <&ccu CLK_AUDIO_CODEC_ADC>;
			clock-names	= "clk_bus_audio_codec",
					  "clk_pll_audio_1x",
					  "clk_audio_dac",
					  "clk_audio_adc";
			status = "disabled";
		};

		codec_plat:codec_plat {
			#sound-dai-cells = <0>;
			compatible	= "allwinner,sunxi-snd-plat-aaudio";
			dac-txdata	= <0x02030020>;
			adc-txdata	= <0x02030040>;
			dmas		= <&dma 7>, <&dma 7>;
			dma-names	= "tx", "rx";
			playback-cma	= <128>;
			capture-cma	= <128>;
			tx-fifo-size	= <128>;
			rx-fifo-size	= <128>;
			status = "disabled";
		};

		codec_mach:codec_mach {
			compatible	= "allwinner,sunxi-snd-mach";
			soundcard-mach,name = "audiocodec";
			soundcard-mach,pin-switches = "MIC1", "MIC2", "LINEINL",
						      "LINEINR", "LINEOUT", "SPK";
			soundcard-mach,routing = "MIC1_PIN",	"MIC1",
						 "MIC2_PIN",	"MIC2",
						 "LINEINL_PIN",	"LINEINL",
						 "LINEINR_PIN",	"LINEINR",
						 "LINEOUT",	"LINEOUTL_PIN",
						 "SPK",		"LINEOUTL_PIN";
			status = "disabled";
			soundcard-mach,cpu {
				sound-dai = <&codec_plat>;
			};
			soundcard-mach,codec {
				/* pll freq = 24.576M or 22.5792M * pll-fs */
				soundcard-mach,pll-fs = <1>;
				sound-dai = <&codec>;
			};
		};

		/* audio dirver module -> DMIC */
		dmic_plat:dmic_plat@0x02031000 {
			#sound-dai-cells = <0>;
			compatible	= "allwinner,sunxi-snd-plat-dmic";
			reg		= <0x0 0x02031000 0x0 0x50>;
			resets		= <&ccu RST_BUS_DMIC>;
			clocks		= <&ccu CLK_BUS_DMIC>,
					  <&ccu CLK_PLL_AUDIO_1X>,
					  <&ccu CLK_DMIC>;
			clock-names	= "clk_bus_dmic",
					  "clk_pll_audio_1x",
					  "clk_dmic";
			dmas		= <&dma 8>;
			dma-names	= "rx";
			capture-cma	= <128>;
			rx-fifo-size	= <128>;
			status = "disabled";
		};

		dmic_mach:dmic_mach{
			compatible	= "allwinner,sunxi-snd-mach";
			soundcard-mach,name = "snddmic";
			soundcard-mach,capture-only;
			status = "disabled";
			soundcard-mach,cpu {
				sound-dai = <&dmic_plat>;
			};
			soundcard-mach,codec {
			};
		};

		/* audio dirver module -> I2S/PCM */
		i2s0_plat:i2s0_plat@0x02032000 {
			#sound-dai-cells = <0>;
			compatible	= "allwinner,sunxi-snd-plat-i2s";
			reg		= <0x0 0x02032000 0x0 0x7c>;
			resets		= <&ccu RST_BUS_I2S0>;
			clocks		= <&ccu CLK_BUS_I2S0>,
					  <&ccu CLK_PLL_AUDIO_1X>,
					  <&ccu CLK_I2S0>;
			clock-names	= "clk_bus_i2s",
					  "clk_pll_audio_1x",
					  "clk_i2s";
			dmas		= <&dma 3>, <&dma 3>;
			dma-names	= "tx", "rx";
			playback-cma	= <128>;
			capture-cma	= <128>;
			tx-fifo-size	= <128>;
			rx-fifo-size	= <128>;
			status = "disabled";
		};

		i2s0_mach:i2s0_mach{
			compatible	= "allwinner,sunxi-snd-mach";
			soundcard-mach,name		= "sndi2s0";
			soundcard-mach,format		= "i2s";
			soundcard-mach,slot-num		= <2>;
			soundcard-mach,slot-width	= <32>;
			status = "disabled";
			soundcard-mach,cpu {
				sound-dai = <&i2s0_plat>;
			};
			soundcard-mach,codec {
			};
		};

		i2s1_plat:i2s1_plat@0x02033000 {
			#sound-dai-cells = <0>;
			compatible	= "allwinner,sunxi-snd-plat-i2s";
			reg		= <0x0 0x02033000 0x0 0x7c>;
			resets		= <&ccu RST_BUS_I2S1>;
			clocks		= <&ccu CLK_BUS_I2S1>,
					  <&ccu CLK_PLL_AUDIO_1X>,
					  <&ccu CLK_I2S1>;
			clock-names	= "clk_bus_i2s",
					  "clk_pll_audio_1x",
					  "clk_i2s";
			dmas		= <&dma 4>, <&dma 4>;
			dma-names	= "tx", "rx";
			playback-cma	= <128>;
			capture-cma	= <128>;
			tx-fifo-size	= <128>;
			rx-fifo-size	= <128>;
			status = "disabled";
		};

		i2s1_mach:i2s1_mach{
			compatible	= "allwinner,sunxi-snd-mach";
			soundcard-mach,name		= "sndi2s1";
			soundcard-mach,format		= "i2s";
			soundcard-mach,slot-num		= <2>;
			soundcard-mach,slot-width	= <32>;
			status = "disabled";
			soundcard-mach,cpu {
				sound-dai = <&i2s1_plat>;
			};
			soundcard-mach,codec {
			};
		};
		/* audio dirver module -> END */

		rfkill: rfkill {
			compatible = "allwinner,sunxi-rfkill";
			status = "disabled";
		};

		addr_mgt: addr_mgt {
			compatible = "allwinner,sunxi-addr_mgt";
			status = "disabled";
		};

		btlpm: btlpm {
			compatible = "allwinner,sunxi-btlpm";
			status = "disabled";
		};

		pwm: pwm@2000c00 {
			#pwm-cells = <0x3>;
			compatible = "allwinner,sunxi-pwm-v201";
			reg = <0x0 0x02000c00 0x0 0x400>;
			interrupts = <GIC_SPI 18 IRQ_TYPE_LEVEL_HIGH>;
			clocks = <&ccu CLK_PWM>;
			resets = <&ccu RST_BUS_PWM>;
			pwm-number = <12>;
			pwm-base = <0x0>;
			sunxi-pwms = <&pwm0>, <&pwm1>, <&pwm2>, <&pwm3>,
				<&pwm4>, <&pwm5>, <&pwm6>, <&pwm7>, <&pwm8>, <&pwm9>,
				<&pwm10>, <&pwm11>;
			status = "okay";
		};

		pwm0: pwm0@2000c10 {
			compatible = "allwinner,sunxi-pwm0";
			pinctrl-names = "active", "sleep";
			reg = <0x0 0x02000c10 0x0 0x4>;
			reg_base = <0x02000c00>;
			status = "disabled";
		};

		pwm1: pwm1@2000c11 {
			compatible = "allwinner,sunxi-pwm1";
			pinctrl-names = "active", "sleep";
			reg = <0x0 0x02000c11 0x0 0x4>;
			reg_base = <0x02000c00>;
			status = "disabled";
		};

		pwm2: pwm2@2000c12 {
			compatible = "allwinner,sunxi-pwm2";
			pinctrl-names = "active", "sleep";
			reg = <0x0 0x02000c12 0x0 0x4>;
			reg_base = <0x02000c00>;
			status = "disabled";
		};

		pwm3: pwm3@2000c13 {
			compatible = "allwinner,sunxi-pwm3";
			pinctrl-names = "active", "sleep";
			reg = <0x0 0x02000c13 0x0 0x4>;
			reg_base = <0x02000c00>;
			status = "disabled";
		};

		pwm4: pwm4@2000c14 {
			compatible = "allwinner,sunxi-pwm4";
			pinctrl-names = "active", "sleep";
			reg = <0x0 0x02000c14 0x0 0x4>;
			reg_base = <0x02000c00>;
			status = "disabled";
		};

		pwm5: pwm5@2000c15 {
			compatible = "allwinner,sunxi-pwm5";
			pinctrl-names = "active", "sleep";
			reg = <0x0 0x02000c15 0x0 0x4>;
			reg_base = <0x02000c00>;
			status = "disabled";
		};

		pwm6: pwm6@2000c16 {
			compatible = "allwinner,sunxi-pwm6";
			pinctrl-names = "active", "sleep";
			reg = <0x0 0x02000c16 0x0 0x4>;
			reg_base = <0x02000c00>;
			status = "disabled";
		};

		pwm7: pwm7@2000c17 {
			compatible = "allwinner,sunxi-pwm7";
			pinctrl-names = "active", "sleep";
			reg = <0x0 0x02000c17 0x0 0x4>;
			reg_base = <0x02000c00>;
			status = "disabled";
		};

		pwm8: pwm8@2000c18 {
			compatible = "allwinner,sunxi-pwm8";
			pinctrl-names = "active", "sleep";
			reg = <0x0 0x02000c18 0x0 0x4>;
			reg_base = <0x02000c00>;
			status = "disabled";
		};

		pwm9: pwm9@2000c19 {
			compatible = "allwinner,sunxi-pwm9";
			pinctrl-names = "active", "sleep";
			reg = <0x0 0x02000c19 0x0 0x4>;
			reg_base = <0x02000c00>;
			status = "disabled";
		};

		pwm10: pwm10@2000c1a {
			compatible = "allwinner,sunxi-pwm10";
			pinctrl-names = "active", "sleep";
			reg = <0x0 0x02000c1a 0x0 0x4>;
			reg_base = <0x02000c00>;
			status = "disabled";
		};

		pwm11: pwm11@2000c1b {
			compatible = "allwinner,sunxi-pwm11";
			pinctrl-names = "active", "sleep";
			reg = <0x0 0x02000c1b 0x0 0x4>;
			reg_base = <0x02000c00>;
			status = "disabled";
		};

		lcd_fb0: lcd_fb0@0 {
			compatible = "allwinner,sunxi-lcd_fb0";
			pinctrl-names = "active","sleep";
			status = "disabled";
		};

		/*
		 * channel0~3 : arm -> risc-v
		 */
		msgbox: msgbox@3003000 {
			compatible = "allwinner,sun8iw21-msgbox";
			#mbox-cells = <1>;
			reg = <0x0 0x03003000 0x0 0x1000>,
			      <0x0 0x06020000 0x0 0x1000>;
			interrupts = <GIC_SPI 0 IRQ_TYPE_LEVEL_HIGH>,
					<GIC_SPI 1 IRQ_TYPE_LEVEL_HIGH>;
			clocks = <&ccu CLK_MSGBOX0>;
			clock-names = "msgbox";
			resets = <&ccu RST_BUS_MSGBOX0>;
			reset-names = "rst";
			local_id = <0>;
		};

		e907_rproc: e907_rproc@6010000 {
			reg = <0x0 0x06010000 0x0 0x1000>;
			compatible = "allwinner,e907-rproc";

			core-clock-frequency = <600000000>;
			axi-clock-frequency = <300000000>;
			clocks = <&ccu CLK_PLL_PERI_600M>, <&ccu CLK_E907_CORE_DIV>, <&ccu CLK_E907_CORE_GATE>, <&ccu CLK_E907_AXI_DIV>, <&ccu CLK_RISCV_CFG>, <&ccu CLK_E907_CORE_RST>, <&ccu CLK_E907_DBG_RST>;
			clock-names = "input", "core-div", "core-gate", "axi-div", "rv-cfg-gate", "core-rst", "dbg-rst";
			resets = <&ccu RST_BUS_RISCV_CFG>;
			reset-names = "rv-cfg-rst";

			firmware-name = "amp_rv0.bin";
			reg-names = "rv-cfg";

			mboxes = <&msgbox 0>, <&msgbox 2>;
			mbox-names = "arm-kick", "arm-standby";
			status = "disabled";
		};
	};
};
